AUTOSAR XML (schema 4-2-1)
package /ComponentTypes
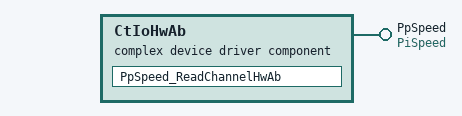
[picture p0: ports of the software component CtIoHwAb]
  complex device driver sw component type CtIoHwAb
    provide port PpSpeed: server-com-spec{operation=ReadChannel, queue-length=1}, provided-interface=PiSpeed
    behavior CtIoHwAb_InternalBehavior: data-type-mapping=ApMappingSet
      operation invoked event OIT_PpSpeed_ReadChannelHwAb_PpSpeed_ReadChannel: start-on-event=PpSpeed_ReadChannelHwAb, operation=PpSpeed.ReadChannel
      runnable PpSpeed_ReadChannelHwAb
  swc implementation CtIoHwAb_Implementation: behavior=CtIoHwAb_InternalBehavior
    code-descriptors:
      code Default: artifact-descriptors=autosar-engineering-object={short-label=Default, category=SWSRC}
